# ADuCM410 register map
Vendor: Analog Devices; Series: ADuCM410; File version: 1p0
CPU: CM33 r0p1, little endian, MPU, FPU, 3 interrupt priority bits
Registers are 32-bit, read-write, reset 0x0 unless marked. A register's access mark holds for its fields unless they carry their own. Offsets are from the block's base; [hi:lo] are bit positions; {n}, {i} and the like mark numbered series; 'fields as' and 'values as' point back to an identical list.

## CLK
Base 0x40060000
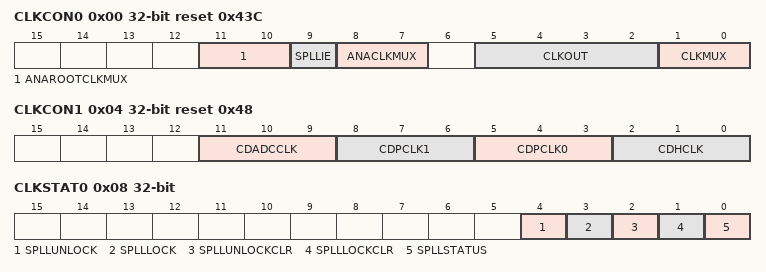
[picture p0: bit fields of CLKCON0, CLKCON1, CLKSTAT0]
0x00 CLKCON0 reset 0x43C — Misc Clock Settings Register
  [11:10] ANAROOTCLKMUX — Clock Mux Select
    0=OSC16 (16MHz Oscillator Clock); 1=OSC32 (32MHz Oscillator Clock); 2=PLL (PLL Clock); 3=GPIO (External GPIO Clock)
  [9] SPLLIE — PLL Unlock and Lock Interrupt Enable
    0=DIS (PLL Interrupt Will Not Be Generated); 1=EN (PLL Interrupt Will Be Generated)
  [8:7] ANACLKMUX — Mux Selection Analog Clock Source
    0=HFOSC (Internal Oscillator is Selected (HFOSC)); 2=GPIOCLK (GPIO Clock)
  [5:2] CLKOUT — GPIO CLK Out Select
    0=HFOSC (HFOSC (16 MHz)); 1=ROOT (Root Clock); 3=LFOSC (32K OSC); 4=CORE (Core Clock); 5=B0_PCLK (Bridge 0 Pclk); 6=B1_PCLK (Bridge 1 PCLK); 7=B2_PCLK (Bridge 2 PCLK); 8=ana_clk (Analog Test Signal); 9=T0 (Timer 0 Clock); 10=WUT (Wake up Timer Clock); 11=T3 (Timer 3 Clock); 12=HCLKBUS; 13=SPLL_CLK (SPLL clock)
  [1:0] CLKMUX — Clock Mux Select
    0=HFOSC (High Frequency Internal Oscillator (HFOSC)); 1=SPLL (System PLL is Selected (160 MHz)); 3=EXTCLK (External GPIO Port is Selected (ECLKIN))
0x04 CLKCON1 reset 0x48 — Clock Dividers Register
  [11:9] CDADCCLK — ADCCLK Divide Bits
    0=DIV1 (DIV1. Divide by 1 (ADCCLK is Equal to Root Clock)); 1=DIV2 (DIV2. Divide by 2 (ADCCLK is Half the Frequency of Root Clock)); 2=DIV4 (DIV4. Divide by 4 (ADCCLK is Quarter the Frequency of Root Clock, 20 MHz)); 3=DIV8 (DIV8. Divide by 8); 4=DIV16 (DIV16. Divide by 16); 5=DIV32 (DIV32. Divide by 32); 6=DIV64 (DIV64. Divide by 164); 7=DIV128 (DIV128. Divide by 128)
  [8:6] CDPCLK1 — APB1 PCLK Divide Bits
    0=DIV1 (DIV1. Divide by 1 (PCLK is Equal to Root Clock)); 1=DIV2 (DIV2. Divide by 2 (PCLK is Half the Frequency of Root Clock)); 2=DIV4 (DIV4. Divide by 4 (PCLK is Quarter the Frequency of Root Clock, 20 MHz)); 3=DIV8 (DIV8. Divide by 8); 4=DIV16 (DIV16. Divide by 16); 5=DIV32 (DIV32. Divide by 32); 6=DIV64 (DIV64. Divide by 164); 7=DIV128 (DIV128. Divide by 128)
  [5:3] CDPCLK0 — APB0 PCLK Divide Bits
    values as CDPCLK1
  [2:0] CDHCLK — HCLK Divide Bits
    0=DIV1 (DIV1. Divide by 1 (HCLK is Equal to Root Clock)); 1=DIV2 (DIV2. Divide by 2 (HCLK is Half the Frequency of Root Clock)); 2=DIV4 (DIV4. Divide by 4 (HCLK is Quarter the Frequency of Root Clock)); 3=DIV8 (DIV8. Divide by 8); 4=DIV16 (DIV16.Divide by 16); 5=DIV32 (DIV32.Divide by 32); 6=DIV64 (DIV64.Divide by 64); 7=DIV128 (DIV128. Divide by 128)
0x08 CLKSTAT0 — Clocking Status
  [4] SPLLUNLOCK ro — Sticky System PLL Unlock Flag
    0=UNLOCKED (No PLL Lock Event Was Detected); 1=LOCKED (A PLL Lock Event Was Detected)
  [3] SPLLLOCK ro — Sticky System PLL Lock Flag
    values as SPLLUNLOCK
  [2] SPLLUNLOCKCLR — System PLL Unlock
    0=NOLOSS (No Loss of PLL Lock Was Detected); 1=LOSS (A PLL Loss of Lock Was Detected)
  [1] SPLLLOCKCLR — System PLL Lock
    values as SPLLUNLOCK
  [0] SPLLSTATUS ro — System PLL Status
    0=UNLOCKED (The PLL is Not Locked or Not Properly Configured. the PLL is Not Ready for Use as the System Clock Source); 1=LOCKED (The PLL is Locked and is Ready for Use as the System Clock Source)

## PWM
Base 0x40064000
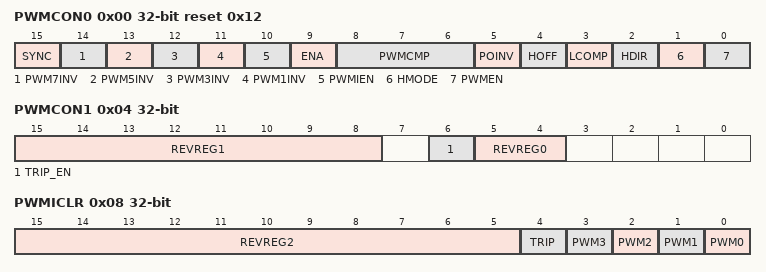
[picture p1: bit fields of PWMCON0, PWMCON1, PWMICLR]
0x00 PWMCON0 reset 0x12 — PWM Control Register
  [15] SYNC — Set to Enable PWM Synchronization from the SYNC Pin
    0=DIS (Ignore Transition from the SYNC Pin); 1=EN (All PWM Counters are Reset on the Next Clock Cycle After Detection of a Falling Edge from SYNC Pin)
  [14] PWM7INV range 0x00000000..0x00000001 — Set to Invert PWM7 Output
  [13] PWM5INV range 0x00000000..0x00000001 — Set to Invert PWM5 Output
  [12] PWM3INV range 0x00000000..0x00000001 — Set to Invert PWM3 Output
  [11] PWM1INV range 0x00000000..0x00000001 — Set to Invert PWM1 Output
  [10] PWMIEN range 0x00000000..0x00000001 — Set to Enable Interrupts for PWM
  [9] ENA — Enable for Pair 0 and 1 When HOFF=0 and HMODE=1
    0=DIS (Disable Pair 0 and 1); 1=EN (Enable Pair 0 and 1)
  [8:6] PWMCMP — PWM Clock Prescaler. Sets UCLK Divider.
    0=DIV2 (UCLK/2); 1=DIV4 (UCLK/4); 2=DIV8 (UCLK/8); 3=DIV16 (UCLK/16); 4=DIV32 (UCLK/32); 5=DIV64 (UCLK/64); 6=DIV128 (UCLK/128); 7=DIV256 (UCLK/256)
  [5] POINV range 0x00000000..0x00000001 — Set to Invert PWM Outputs for Pair 0/1 in H-bridge Mode
  [4] HOFF range 0x00000000..0x00000001 — Set to Turn off the High-side for Pair 0/1 in H-bridge Mode
  [3] LCOMP — Signal to Load a New Set of Compare Register Values
    0=DIS (Use the Values Previously Store in the Compare and Length Registers); 1=EN (Load the Internal Compare Registers with Values Stored in the PWMxCOMx and PWMxLEN Registers)
  [2] HDIR — Direction Control When PWM is in H-bridge Mode
    0=DIS (PWM2 and PWM3 Act as Output Signals While PWM0 and PWM1 are Held Low); 1=EN (PWM0 and PWM1 Act as Output Signals While PWM2 and PWM3 are Held Low)
  [1] HMODE range 0x00000000..0x00000001 — Set to Enable H-bridge Mode
  [0] PWMEN — Master Enable for PWM
    0=DIS (Disable All PWM Outputs); 1=EN (Enable All PWM Outputs)
0x04 PWMCON1 — ADC Conversion Start and Trip Control Register
  [15:8] REVREG1 ro — Reserved. Return 0 on Reads
  [6] TRIP_EN range 0x00000000..0x00000001 — Set to Enable PWM Trip Functionality
  [5:4] REVREG0 ro — Reserved
0x08 PWMICLR — Hardware Trip Configuration Register
  [15:5] REVREG2 ro — Reserved. Return 0 on Reads
  [4] TRIP range 0x00000000..0x00000001 — Write a 1 to Clear Latched IRQPWMTrip Interrupt.
  [n] PWM{n} range 0x00000000..0x00000001 (n=0..3) — Write a 1 to Clear Latched IRQPWM{n} Interrupt.
{0x10+0x10*i} PWM{i}COM0 (i=0..3) — Compare Register 0 for PWM{2i} and PWM{2i+1}
  [15:0] PWM{i}COM0 range 0x00000000..0x0000FFFF
{0x14+0x10*i} PWM{i}COM1 (i=0..3) — Compare Register 1 for PWM{2i} and PWM{2i+1}
  [15:0] PWM{i}COM1 range 0x00000000..0x0000FFFF
{0x18+0x10*i} PWM{i}COM2 (i=0..3) — Compare Register 2 for PWM{2i} and PWM{2i+1}
  [15:0] PWM{i}COM2 range 0x00000000..0x0000FFFF
{0x1C+0x10*i} PWM{i}LEN (i=0..3) — Period Value Register for PWM{2i} and PWM{2i+1}
  [15:0] PWM{i}LEN range 0x00000000..0x0000FFFF
